# ATmega16HVBrevB register map
Vendor: Atmel; File version: 1.0
CPU: other r0p0, little endian, no MPU, no FPU, 4 interrupt priority bits
Registers are 8-bit, read-write, reset 0x0 unless marked. A register's access mark holds for its fields unless they carry their own. Offsets are from the block's base; [hi:lo] are bit positions.

## PORTC — I/O Port
Base 0x00000026
0x00 PINC — Port C Input Pins
0x02 PORTC — Port C Data Register

## SPI — Serial Peripheral Interface
Base 0x0000004C
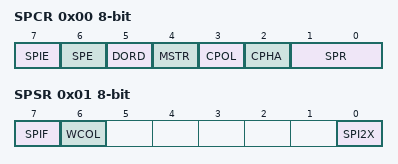
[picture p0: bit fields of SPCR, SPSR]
0x00 SPCR — SPI Control Register
  [7] SPIE — SPI Interrupt Enable
  [6] SPE — SPI Enable
  [5] DORD — Data Order
  [4] MSTR — Master/Slave Select
  [3] CPOL — Clock polarity
  [2] CPHA — Clock Phase
  [1:0] SPR — SPI Clock Rate Selects
    0=fosc/4; 1=fosc/16; 2=fosc/64; 3=fosc/128
0x01 SPSR — SPI Status Register
  [7] SPIF — SPI Interrupt Flag
  [6] WCOL — Write Collision Flag
  [0] SPI2X — Double SPI Speed Bit
0x02 SPDR — SPI Data Register
  [7:0] SPDR — SPI Data bits

## TC0 — Timer/Counter, 16-bit
Base 0x00000035
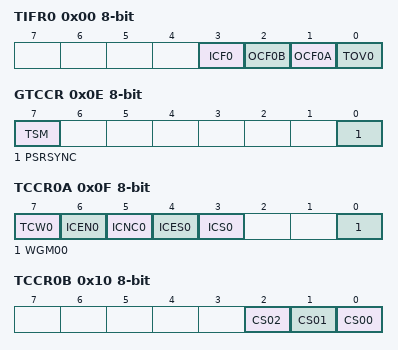
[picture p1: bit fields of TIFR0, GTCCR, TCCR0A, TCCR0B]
0x00 TIFR0 — Timer/Counter Interrupt Flag register
  [3] ICF0 — Timer/Counter 0 Input Capture Flag
  [2] OCF0B — Timer/Counter0 Output Compare Flag B
  [1] OCF0A — Timer/Counter0 Output Compare Flag A
  [0] TOV0 — Timer/Counter0 Overflow Flag
0x0E GTCCR — General Timer/Counter Control Register
  [7] TSM — Timer/Counter Synchronization Mode
  [0] PSRSYNC — Prescaler Reset
0x0F TCCR0A — Timer/Counter 0 Control Register A
  [7] TCW0 — Timer/Counter Width
  [6] ICEN0 — Input Capture Mode Enable
  [5] ICNC0 — Input Capture Noise Canceler
  [4] ICES0 — Input Capture Edge Select
  [3] ICS0 — Input Capture Select
  [0] WGM00 — Waveform Generation Mode
0x10 TCCR0B — Timer/Counter0 Control Register B
  [2] CS02 — Clock Select0 bit 2
  [1] CS01 — Clock Select0 bit 1
  [0] CS00 — Clock Select0 bit 0
    0=No Clock Source (Stopped); 1=Running, No Prescaling
0x11 TCNT0 16-bit (reset mask 0xFF) — Timer Counter 0 Bytes
  [15:0] TCNT0 — Timer Counter 0 bits
0x13 OCR0A — Output Compare Register 0A
  [7:0] OCR0A — Output Compare 0 A bits
0x14 OCR0B — Output Compare Register B
  [7:0] OCR0B — Output Compare 0 B bits
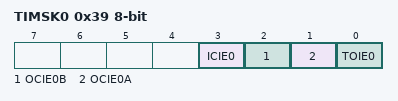
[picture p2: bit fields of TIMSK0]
0x39 TIMSK0 — Timer/Counter Interrupt Mask Register
  [3] ICIE0 — Timer/Counter n Input Capture Interrupt Enable
  [2] OCIE0B — Timer/Counter0 Output Compare B Interrupt Enable
  [1] OCIE0A — Timer/Counter0 Output Compare A Interrupt Enable
  [0] TOIE0 — Timer/Counter0 Overflow Interrupt Enable

## TC1 — Timer/Counter, 16-bit
Base 0x00000036
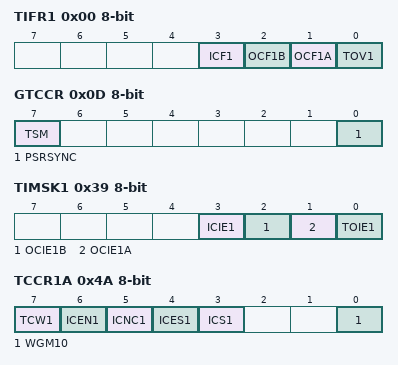
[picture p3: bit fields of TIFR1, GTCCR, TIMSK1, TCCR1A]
0x00 TIFR1 — Timer/Counter Interrupt Flag register
  [3] ICF1 — Timer/Counter 1 Input Capture Flag
  [2] OCF1B — Timer/Counter1 Output Compare Flag B
  [1] OCF1A — Timer/Counter1 Output Compare Flag A
  [0] TOV1 — Timer/Counter1 Overflow Flag
0x0D GTCCR — General Timer/Counter Control Register
  [7] TSM — Timer/Counter Synchronization Mode
  [0] PSRSYNC — Prescaler Reset
0x39 TIMSK1 — Timer/Counter Interrupt Mask Register
  [3] ICIE1 — Timer/Counter n Input Capture Interrupt Enable
  [2] OCIE1B — Timer/Counter1 Output Compare B Interrupt Enable
  [1] OCIE1A — Timer/Counter1 Output Compare A Interrupt Enable
  [0] TOIE1 — Timer/Counter1 Overflow Interrupt Enable
0x4A TCCR1A — Timer/Counter 1 Control Register A
  [7] TCW1 — Timer/Counter Width
  [6] ICEN1 — Input Capture Mode Enable
  [5] ICNC1 — Input Capture Noise Canceler
  [4] ICES1 — Input Capture Edge Select
  [3] ICS1 — Input Capture Select
  [0] WGM10 — Waveform Generation Mode
0x4B TCCR1B — Timer/Counter1 Control Register B
  [2:0] CS — Clock Select1 bis
    0=No Clock Source (Stopped); 1=Running, No Prescaling; 2=Running, CLK/8; 3=Running, CLK/64; 4=Running, CLK/256; 5=Running, CLK/1024; 6=Running, ExtClk Tx Falling Edge; 7=Running, ExtClk Tx Rising Edge
0x4E TCNT1 16-bit (reset mask 0xFF) — Timer Counter 1 Bytes
  [15:0] TCNT1 — Timer Counter 1 bits
0x52 OCR1A — Output Compare Register 1A
  [7:0] OCR1A — Output Compare 1 A bits
0x53 OCR1B — Output Compare Register B
  [7:0] OCR1B — Output Compare 1 B bits

## TWI — Two Wire Serial Interface
Base 0x000000B8
0x00 TWBR — TWI Bit Rate register
  [7:0] TWBR — TWI Bit Rate bits
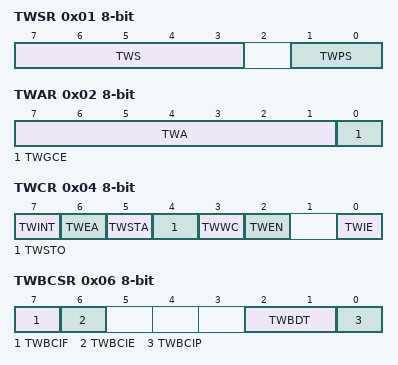
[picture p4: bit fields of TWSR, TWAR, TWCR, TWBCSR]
0x01 TWSR — TWI Status Register
  [7:3] TWS — TWI Status
  [1:0] TWPS — TWI Prescaler
    0=1; 1=4; 2=16; 3=64
0x02 TWAR — TWI (Slave) Address register
  [7:1] TWA — TWI (Slave) Address register Bits
  [0] TWGCE — TWI General Call Recognition Enable Bit
0x03 TWDR — TWI Data register
  [7:0] TWD — TWI Data Bits
0x04 TWCR — TWI Control Register
  [7] TWINT — TWI Interrupt Flag
  [6] TWEA — TWI Enable Acknowledge Bit
  [5] TWSTA — TWI Start Condition Bit
  [4] TWSTO — TWI Stop Condition Bit
  [3] TWWC — TWI Write Collition Flag
  [2] TWEN — TWI Enable Bit
  [0] TWIE — TWI Interrupt Enable
0x05 TWAMR — TWI (Slave) Address Mask Register
  [7:1] TWAM
0x06 TWBCSR — TWI Bus Control and Status Register
  [7] TWBCIF — TWI Bus Connect/Disconnect Interrupt Flag
  [6] TWBCIE — TWI Bus Connect/Disconnect Interrupt Enable
  [2:1] TWBDT — TWI Bus Disconnect Time-out Period
    0=250ms; 1=500ms; 2=1000ms; 3=2000ms
  [0] TWBCIP — TWI Bus Connect/Disconnect Interrupt Polarity

## VOLTAGE_REGULATOR
Base 0x000000C8
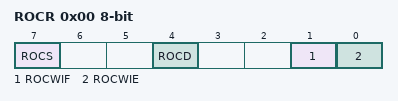
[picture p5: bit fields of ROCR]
0x00 ROCR — Regulator Operating Condition Register
  [7] ROCS — ROC Status
  [4] ROCD — ROC Disable
  [1] ROCWIF — ROC Warning Interrupt Flag
  [0] ROCWIE — ROC Warning Interrupt Enable

## WDT — Watchdog Timer
Base 0x00000060
0x00 WDTCSR — Watchdog Timer Control Register
  [7] WDIF — Watchdog Timeout Interrupt Flag
  [6] WDIE — Watchdog Timeout Interrupt Enable
  [4] WDCE — Watchdog Change Enable
  [3] WDE — Watch Dog Enable
  [5:0] WDP — Watchdog Timer Prescaler Bits
    0=Oscillator Cycles 2K; 1=Oscillator Cycles 4K; 2=Oscillator Cycles 8K; 3=Oscillator Cycles 16K; 4=Oscillator Cycles 32K; 5=Oscillator Cycles 64K; 6=Oscillator Cycles 128K; 7=Oscillator Cycles 256K
